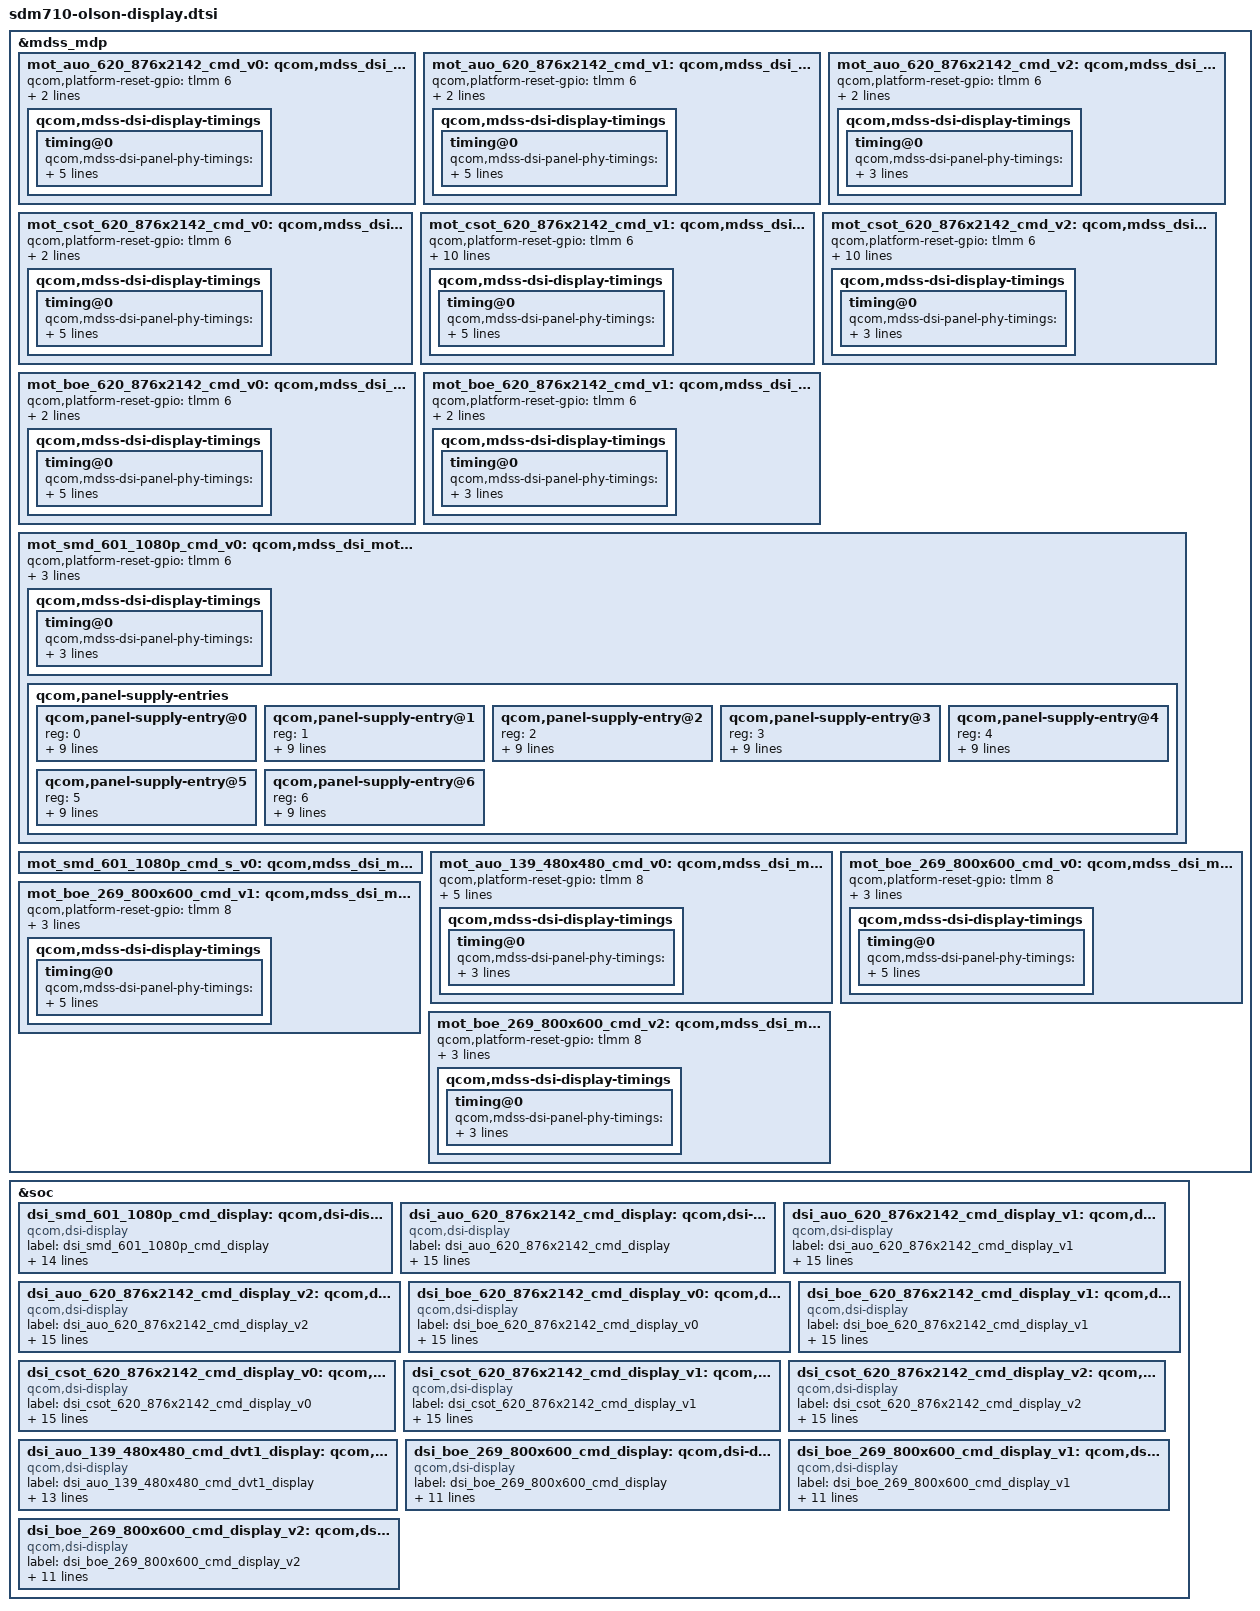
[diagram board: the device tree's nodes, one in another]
/* Copyright (c) 2019, The Linux Foundation. All rights reserved.
 *
 * This program is free software; you can redistribute it and/or modify
 * it under the terms of the GNU General Public License version 2 and
 * only version 2 as published by the Free Software Foundation.
 *
 * This program is distributed in the hope that it will be useful,
 * but WITHOUT ANY WARRANTY; without even the implied warranty of
 * MERCHANTABILITY or FITNESS FOR A PARTICULAR PURPOSE.  See the
 * GNU General Public License for more details.
 */

&mdss_mdp {
	/* Primary Display: AUO */
	mot_auo_620_876x2142_cmd_v0: qcom,mdss_dsi_mot_auo_620_876x2142_cmd_v0 {
		#include "dsi-panel-mot-auo-620-876x2142-olson-cmd-common.dtsi"
	};

	mot_auo_620_876x2142_cmd_v1: qcom,mdss_dsi_mot_auo_620_876x2142_cmd_v1 {
		#include "dsi-panel-mot-auo-620-876x2142-olson-cmd-common.dtsi"
	};

	mot_auo_620_876x2142_cmd_v2: qcom,mdss_dsi_mot_auo_620_876x2142_cmd_v2 {
		#include "dsi-panel-mot-auo-620-876x2142-olson-cmd-common.dtsi"
	};

        /* Primary Display:  CSOT */
        mot_csot_620_876x2142_cmd_v0: qcom,mdss_dsi_mot_csot_620_876x2142_cmd_v0 {
		#include "dsi-panel-mot-csot-620-876x2142-olson-cmd-common.dtsi"
	};

	mot_csot_620_876x2142_cmd_v1: qcom,mdss_dsi_mot_csot_620_876x2142_cmd_v1 {
		#include "dsi-panel-mot-csot-620-876x2142-olson-cmd-common.dtsi"
	};
	mot_csot_620_876x2142_cmd_v2: qcom,mdss_dsi_mot_csot_620_876x2142_cmd_v2 {
		#include "dsi-panel-mot-csot-620-876x2142-olson-cmd-common.dtsi"
	};
	/* Primary Display:  BOE */
	mot_boe_620_876x2142_cmd_v0: qcom,mdss_dsi_mot_boe_620_876x2142_cmd_v0 {
		#include "dsi-panel-mot-boe-620-876x2142-olson-cmd-common.dtsi"
	};

	/* Primary Display:  BOE */
	mot_boe_620_876x2142_cmd_v1: qcom,mdss_dsi_mot_boe_620_876x2142_cmd_v1 {
		#include "dsi-panel-mot-boe-620-876x2142-olson-cmd-common.dtsi"
	};

	/* Primary Display:  SMD */
	mot_smd_601_1080p_cmd_v0: qcom,mdss_dsi_mot_smd_601_1080p_cmd_v0 {
		#include "dsi-panel-mot-smd-601-1080p-olson-cmd-common.dtsi"
	};

	mot_smd_601_1080p_cmd_s_v0: qcom,mdss_dsi_mot_smd_601_1080p_cmd_s_v0 {
		#include "dsi-panel-mot-smd-601-1080p-olson-cmd-common.dtsi"
	};

	/* Secondary Display: AUO */
	mot_auo_139_480x480_cmd_v0: qcom,mdss_dsi_mot_auo_139_480x480_cmd_v0 {
		#include "dsi-panel-mot-auo-139-480x480-olson-cmd-common.dtsi"
	};

	/* Secondary Display: BOE */
	mot_boe_269_800x600_cmd_v0: qcom,mdss_dsi_mot_boe_269_800x600_cmd_v0 {
		#include "dsi-panel-mot-boe-269-800x600-olson-cmd-common.dtsi"
	};

	mot_boe_269_800x600_cmd_v1: qcom,mdss_dsi_mot_boe_269_800x600_cmd_v1 {
		#include "dsi-panel-mot-boe-269-800x600-olson-cmd-common.dtsi"
	};

	mot_boe_269_800x600_cmd_v2: qcom,mdss_dsi_mot_boe_269_800x600_cmd_v2 {
		#include "dsi-panel-mot-boe-269-800x600-olson-cmd-common.dtsi"
	};
};

&soc {
	/* Please keep all the "primary" panel nodes together */
	dsi_smd_601_1080p_cmd_display: qcom,dsi-display@18 {
		compatible = "qcom,dsi-display";
		label = "dsi_smd_601_1080p_cmd_display";
		qcom,display-type = "primary";

		qcom,dsi-ctrl = <&mdss_dsi0>;
		qcom,dsi-phy = <&mdss_dsi_phy0>;
		clocks = <&mdss_dsi0_pll BYTECLK_MUX_0_CLK>,
			<&mdss_dsi0_pll PCLK_MUX_0_CLK>;
		clock-names = "mux_byte_clk", "mux_pixel_clk";

		pinctrl-names = "panel_active", "panel_suspend";
		pinctrl-0 = <&sde_dsi_active &sde_te_active>;
		pinctrl-1 = <&sde_dsi_suspend &sde_te_suspend>;
		qcom,platform-te-gpio = <&tlmm 10 0>;
		qcom,dsi-panel = <&mot_smd_601_1080p_cmd_v0>;
		vci_disp-supply = <&vci_disp_vreg>;
		vio_disp-supply = <&vio_disp_vreg>;
		lab-supply = <&lab_regulator>;
		ibb-supply = <&ibb_regulator>;
		oledb-supply = <&pm660a_oledb>;
	};

	dsi_auo_620_876x2142_cmd_display: qcom,dsi-display@20 {
		compatible = "qcom,dsi-display";
		label = "dsi_auo_620_876x2142_cmd_display";
		qcom,display-type = "primary";

		qcom,dsi-ctrl = <&mdss_dsi0>;
		qcom,dsi-phy = <&mdss_dsi_phy0>;
		clocks = <&mdss_dsi0_pll BYTECLK_MUX_0_CLK>,
				<&mdss_dsi0_pll PCLK_MUX_0_CLK>;
		clock-names = "mux_byte_clk", "mux_pixel_clk";

		pinctrl-names = "panel_active", "panel_suspend";
		pinctrl-0 = <&sde_dsi_active &sde_te_active>;
		pinctrl-1 = <&sde_dsi_suspend &sde_te_suspend>;
		qcom,platform-te-gpio = <&tlmm 10 0>;
		qcom,dsi-panel = <&mot_auo_620_876x2142_cmd_v0>;
		l11_disp-supply = <&pm660_l11>;
		vci_disp-supply = <&vci_disp_vreg>;
		vio_disp-supply = <&vio_disp_vreg>;
		lab-supply = <&lab_regulator>;
		ibb-supply = <&ibb_regulator>;
		oledb-supply = <&pm660a_oledb>;
	};

	dsi_auo_620_876x2142_cmd_display_v1: qcom,dsi-display@24 {
		compatible = "qcom,dsi-display";
		label = "dsi_auo_620_876x2142_cmd_display_v1";
		qcom,display-type = "primary";

		qcom,dsi-ctrl = <&mdss_dsi0>;
		qcom,dsi-phy = <&mdss_dsi_phy0>;
		clocks = <&mdss_dsi0_pll BYTECLK_MUX_0_CLK>,
				<&mdss_dsi0_pll PCLK_MUX_0_CLK>;
		clock-names = "mux_byte_clk", "mux_pixel_clk";

		pinctrl-names = "panel_active", "panel_suspend";
		pinctrl-0 = <&sde_dsi_active &sde_te_active>;
		pinctrl-1 = <&sde_dsi_suspend &sde_te_suspend>;
		qcom,platform-te-gpio = <&tlmm 10 0>;
		qcom,dsi-panel = <&mot_auo_620_876x2142_cmd_v1>;
		l11_disp-supply = <&pm660_l11>;
		vci_disp-supply = <&vci_disp_vreg>;
		vio_disp-supply = <&vio_disp_vreg>;
		lab-supply = <&lab_regulator>;
		ibb-supply = <&ibb_regulator>;
		oledb-supply = <&pm660a_oledb>;
	};

	dsi_auo_620_876x2142_cmd_display_v2: qcom,dsi-display@26 {
		compatible = "qcom,dsi-display";
		label = "dsi_auo_620_876x2142_cmd_display_v2";
		qcom,display-type = "primary";

		qcom,dsi-ctrl = <&mdss_dsi0>;
		qcom,dsi-phy = <&mdss_dsi_phy0>;
		clocks = <&mdss_dsi0_pll BYTECLK_MUX_0_CLK>,
			<&mdss_dsi0_pll PCLK_MUX_0_CLK>;
		clock-names = "mux_byte_clk", "mux_pixel_clk";

		pinctrl-names = "panel_active", "panel_suspend";
		pinctrl-0 = <&sde_dsi_active &sde_te_active>;
		pinctrl-1 = <&sde_dsi_suspend &sde_te_suspend>;
		qcom,platform-te-gpio = <&tlmm 10 0>;
		qcom,dsi-panel = <&mot_auo_620_876x2142_cmd_v2>;
		l11_disp-supply = <&pm660_l11>;
		vci_disp-supply = <&vci_disp_vreg>;
		vio_disp-supply = <&vio_disp_vreg>;
		lab-supply = <&lab_regulator>;
		ibb-supply = <&ibb_regulator>;
		oledb-supply = <&pm660a_oledb>;
	};

	dsi_boe_620_876x2142_cmd_display_v0: qcom,dsi-display@28 {
		compatible = "qcom,dsi-display";
		label = "dsi_boe_620_876x2142_cmd_display_v0";
		qcom,display-type = "primary";

		qcom,dsi-ctrl = <&mdss_dsi0>;
		qcom,dsi-phy = <&mdss_dsi_phy0>;
		clocks = <&mdss_dsi0_pll BYTECLK_MUX_0_CLK>,
			<&mdss_dsi0_pll PCLK_MUX_0_CLK>;
		clock-names = "mux_byte_clk", "mux_pixel_clk";

		pinctrl-names = "panel_active", "panel_suspend";
		pinctrl-0 = <&sde_dsi_active &sde_te_active>;
		pinctrl-1 = <&sde_dsi_suspend &sde_te_suspend>;
		qcom,platform-te-gpio = <&tlmm 10 0>;
		qcom,dsi-panel = <&mot_boe_620_876x2142_cmd_v0>;
		l11_disp-supply = <&pm660_l11>;
		vci_disp-supply = <&vci_disp_vreg>;
		vio_disp-supply = <&vio_disp_vreg>;
		lab-supply = <&lab_regulator>;
		ibb-supply = <&ibb_regulator>;
		oledb-supply = <&pm660a_oledb>;
	};

	dsi_boe_620_876x2142_cmd_display_v1: qcom,dsi-display@29 {
		compatible = "qcom,dsi-display";
		label = "dsi_boe_620_876x2142_cmd_display_v1";
		qcom,display-type = "primary";

		qcom,dsi-ctrl = <&mdss_dsi0>;
		qcom,dsi-phy = <&mdss_dsi_phy0>;
		clocks = <&mdss_dsi0_pll BYTECLK_MUX_0_CLK>,
			<&mdss_dsi0_pll PCLK_MUX_0_CLK>;
		clock-names = "mux_byte_clk", "mux_pixel_clk";

		pinctrl-names = "panel_active", "panel_suspend";
		pinctrl-0 = <&sde_dsi_active &sde_te_active>;
		pinctrl-1 = <&sde_dsi_suspend &sde_te_suspend>;
		qcom,platform-te-gpio = <&tlmm 10 0>;
		qcom,dsi-panel = <&mot_boe_620_876x2142_cmd_v1>;
		l11_disp-supply = <&pm660_l11>;
		vci_disp-supply = <&vci_disp_vreg>;
		vio_disp-supply = <&vio_disp_vreg>;
		lab-supply = <&lab_regulator>;
		ibb-supply = <&ibb_regulator>;
		oledb-supply = <&pm660a_oledb>;
	};
	dsi_csot_620_876x2142_cmd_display_v0: qcom,dsi-display@30 {
		compatible = "qcom,dsi-display";
		label = "dsi_csot_620_876x2142_cmd_display_v0";
		qcom,display-type = "primary";

		qcom,dsi-ctrl = <&mdss_dsi0>;
		qcom,dsi-phy = <&mdss_dsi_phy0>;
		clocks = <&mdss_dsi0_pll BYTECLK_MUX_0_CLK>,
			<&mdss_dsi0_pll PCLK_MUX_0_CLK>;
		clock-names = "mux_byte_clk", "mux_pixel_clk";

		pinctrl-names = "panel_active", "panel_suspend";
		pinctrl-0 = <&sde_dsi_active &sde_te_active>;
		pinctrl-1 = <&sde_dsi_suspend &sde_te_suspend>;
		qcom,platform-te-gpio = <&tlmm 10 0>;
		qcom,dsi-panel = <&mot_csot_620_876x2142_cmd_v0>;
		l11_disp-supply = <&pm660_l11>;
		vci_disp-supply = <&vci_disp_vreg>;
		vio_disp-supply = <&vio_disp_vreg>;
		lab-supply = <&lab_regulator>;
		ibb-supply = <&ibb_regulator>;
		oledb-supply = <&pm660a_oledb>;
	};

	dsi_csot_620_876x2142_cmd_display_v1: qcom,dsi-display@31 {
		compatible = "qcom,dsi-display";
		label = "dsi_csot_620_876x2142_cmd_display_v1";
		qcom,display-type = "primary";

		qcom,dsi-ctrl = <&mdss_dsi0>;
		qcom,dsi-phy = <&mdss_dsi_phy0>;
		clocks = <&mdss_dsi0_pll BYTECLK_MUX_0_CLK>,
			<&mdss_dsi0_pll PCLK_MUX_0_CLK>;
		clock-names = "mux_byte_clk", "mux_pixel_clk";

		pinctrl-names = "panel_active", "panel_suspend";
		pinctrl-0 = <&sde_dsi_active &sde_te_active>;
		pinctrl-1 = <&sde_dsi_suspend &sde_te_suspend>;
		qcom,platform-te-gpio = <&tlmm 10 0>;
		qcom,dsi-panel = <&mot_csot_620_876x2142_cmd_v1>;
		l11_disp-supply = <&pm660_l11>;
		vci_disp-supply = <&vci_disp_vreg>;
		vio_disp-supply = <&vio_disp_vreg>;
		lab-supply = <&lab_regulator>;
		ibb-supply = <&ibb_regulator>;
		oledb-supply = <&pm660a_oledb>;
	};

	dsi_csot_620_876x2142_cmd_display_v2: qcom,dsi-display@32 {
		compatible = "qcom,dsi-display";
		label = "dsi_csot_620_876x2142_cmd_display_v2";
		qcom,display-type = "primary";

		qcom,dsi-ctrl = <&mdss_dsi0>;
		qcom,dsi-phy = <&mdss_dsi_phy0>;
		clocks = <&mdss_dsi0_pll BYTECLK_MUX_0_CLK>,
			<&mdss_dsi0_pll PCLK_MUX_0_CLK>;
		clock-names = "mux_byte_clk", "mux_pixel_clk";

		pinctrl-names = "panel_active", "panel_suspend";
		pinctrl-0 = <&sde_dsi_active &sde_te_active>;
		pinctrl-1 = <&sde_dsi_suspend &sde_te_suspend>;
		qcom,platform-te-gpio = <&tlmm 10 0>;
		qcom,dsi-panel = <&mot_csot_620_876x2142_cmd_v2>;
		l11_disp-supply = <&pm660_l11>;
		vci_disp-supply = <&vci_disp_vreg>;
		vio_disp-supply = <&vio_disp_vreg>;
		lab-supply = <&lab_regulator>;
		ibb-supply = <&ibb_regulator>;
		oledb-supply = <&pm660a_oledb>;
	};
	/* Please keep all the "secondary" panel nodes together */
	dsi_auo_139_480x480_cmd_dvt1_display: qcom,dsi-display@22 {
		compatible = "qcom,dsi-display";
		label = "dsi_auo_139_480x480_cmd_dvt1_display";
		qcom,display-type = "secondary";

		qcom,dsi-ctrl = <&mdss_dsi1>;
		qcom,dsi-phy = <&mdss_dsi_phy1>;
		clocks = <&mdss_dsi1_pll BYTECLK_MUX_1_CLK>,
			<&mdss_dsi1_pll PCLK_MUX_1_CLK>;
		clock-names = "mux_byte_clk", "mux_pixel_clk";

		pinctrl-names = "panel_active", "panel_suspend";
		pinctrl-0 = <&sde_dsi1_active &sde_te1_active
				&ts_sub_rst_active>;
		pinctrl-1 = <&sde_dsi1_suspend &sde_te1_suspend
				&ts_sub_rst_suspend>;
		qcom,platform-te-gpio = <&tlmm 11 0>;
		qcom,dsi-panel = <&mot_auo_139_480x480_cmd_v0>;
		vci_disp-supply = <&vci_disp_sub_vreg>;
		vio_disp-supply = <&vio_disp_sub_vreg>;
	};

	dsi_boe_269_800x600_cmd_display: qcom,dsi-display@23 {
		compatible = "qcom,dsi-display";
		label = "dsi_boe_269_800x600_cmd_display";
		qcom,display-type = "secondary";

		qcom,dsi-ctrl = <&mdss_dsi1>;
		qcom,dsi-phy = <&mdss_dsi_phy1>;
		clocks = <&mdss_dsi1_pll BYTECLK_MUX_1_CLK>,
			<&mdss_dsi1_pll PCLK_MUX_1_CLK>;
		clock-names = "mux_byte_clk", "mux_pixel_clk";

		pinctrl-names = "panel_active", "panel_suspend";
		pinctrl-0 = <&sde_dsi1_active &sde_te1_active>;
		pinctrl-1 = <&sde_dsi1_suspend &sde_te1_suspend>;
		qcom,platform-te-gpio = <&tlmm 11 0>;
		qcom,dsi-panel = <&mot_boe_269_800x600_cmd_v0>;
		vci_disp-supply = <&vci_disp_sub_vreg>;
		vio_disp-supply = <&vio_disp_sub_vreg>;
	};

	dsi_boe_269_800x600_cmd_display_v1: qcom,dsi-display@25 {
		compatible = "qcom,dsi-display";
		label = "dsi_boe_269_800x600_cmd_display_v1";
		qcom,display-type = "secondary";

		qcom,dsi-ctrl = <&mdss_dsi1>;
		qcom,dsi-phy = <&mdss_dsi_phy1>;
		clocks = <&mdss_dsi1_pll BYTECLK_MUX_1_CLK>,
			<&mdss_dsi1_pll PCLK_MUX_1_CLK>;
		clock-names = "mux_byte_clk", "mux_pixel_clk";

		pinctrl-names = "panel_active", "panel_suspend";
		pinctrl-0 = <&sde_dsi1_active &sde_te1_active>;
		pinctrl-1 = <&sde_dsi1_suspend &sde_te1_suspend>;
		qcom,platform-te-gpio = <&tlmm 11 0>;
		qcom,dsi-panel = <&mot_boe_269_800x600_cmd_v1>;
		vci_disp-supply = <&vci_disp_sub_vreg>;
		vio_disp-supply = <&vio_disp_sub_vreg>;
	};

	dsi_boe_269_800x600_cmd_display_v2: qcom,dsi-display@27 {
		compatible = "qcom,dsi-display";
		label = "dsi_boe_269_800x600_cmd_display_v2";
		qcom,display-type = "secondary";

		qcom,dsi-ctrl = <&mdss_dsi1>;
		qcom,dsi-phy = <&mdss_dsi_phy1>;
		clocks = <&mdss_dsi1_pll BYTECLK_MUX_1_CLK>,
			<&mdss_dsi1_pll PCLK_MUX_1_CLK>;
		clock-names = "mux_byte_clk", "mux_pixel_clk";

		pinctrl-names = "panel_active", "panel_suspend";
		pinctrl-0 = <&sde_dsi1_active &sde_te1_active>;
		pinctrl-1 = <&sde_dsi1_suspend &sde_te1_suspend>;
		qcom,platform-te-gpio = <&tlmm 11 0>;
		qcom,dsi-panel = <&mot_boe_269_800x600_cmd_v2>;
		vci_disp-supply = <&vci_disp_sub_vreg>;
		vio_disp-supply = <&vio_disp_sub_vreg>;
	};
};

&mot_smd_601_1080p_cmd_v0 {
        qcom,platform-reset-gpio = <&tlmm 6 0>;
        qcom,mdss-dsi-t-clk-post = <0x0d>;
        qcom,mdss-dsi-t-clk-pre = <0x30>;
        qcom,mdss-mdp-transfer-time-us = <14000>;

        qcom,mdss-dsi-display-timings {
                timing@0{
                        qcom,mdss-dsi-panel-phy-timings = [00 1f 08 08 24 22 08
                                                        08 05 03 04 00];
                        qcom,display-topology = <1 0 1>;
                        qcom,default-topology-index = <0>;
                };
        };

	qcom,panel-supply-entries {
		#address-cells = <1>;
		#size-cells = <0>;

		qcom,panel-supply-entry@0 {
			reg = <0>;
			qcom,supply-name = "l11_disp";
			qcom,supply-min-voltage = <1800000>;
			qcom,supply-max-voltage = <1800000>;
			qcom,supply-enable-load = <300000>;
			qcom,supply-disable-load = <100>;
			qcom,supply-pre-on-sleep = <0>;
			qcom,supply-post-on-sleep = <1>;
			qcom,supply-pre-off-sleep = <3>;
			qcom,supply-post-off-sleep = <0>;
		};

		qcom,panel-supply-entry@1 {
			reg = <1>;
			qcom,supply-name = "vio_disp";
			qcom,supply-min-voltage = <1800000>;
			qcom,supply-max-voltage = <1800000>;
			qcom,supply-enable-load = <300000>;
			qcom,supply-disable-load = <100>;
			qcom,supply-pre-on-sleep = <0>;
			qcom,supply-post-on-sleep = <2>;
			qcom,supply-pre-off-sleep = <0>;
			qcom,supply-post-off-sleep = <0>;
		};

		qcom,panel-supply-entry@2 {
			reg = <2>;
			qcom,supply-name = "vci_disp";
			qcom,supply-min-voltage = <3200000>;
			qcom,supply-max-voltage = <3200000>;
			qcom,supply-enable-load = <300000>;
			qcom,supply-disable-load = <100>;
			qcom,supply-pre-on-sleep = <0>;
			qcom,supply-post-on-sleep = <2>;
			qcom,supply-pre-off-sleep = <11>;
			qcom,supply-post-off-sleep = <0>;
		};

		qcom,panel-supply-entry@3 {
			reg = <3>;
			qcom,supply-name = "lab";
			qcom,supply-min-voltage = <4600000>;
			qcom,supply-max-voltage = <6100000>;
			qcom,supply-enable-load = <100000>;
			qcom,supply-disable-load = <100>;
			qcom,supply-pre-on-sleep = <0>;
			qcom,supply-post-on-sleep = <0>;
			qcom,supply-pre-off-sleep = <0>;
			qcom,supply-post-off-sleep = <0>;
		};

		qcom,panel-supply-entry@4 {
			reg = <4>;
			qcom,supply-name = "ibb";
			qcom,supply-min-voltage = <4000000>;
			qcom,supply-max-voltage = <6300000>;
			qcom,supply-enable-load = <100000>;
			qcom,supply-disable-load = <100>;
			qcom,supply-pre-on-sleep = <0>;
			qcom,supply-post-on-sleep = <0>;
			qcom,supply-pre-off-sleep = <0>;
			qcom,supply-post-off-sleep = <0>;
		};

		qcom,panel-supply-entry@5 {
			reg = <5>;
			qcom,supply-name = "oledb";
			qcom,supply-min-voltage = <5000000>;
			qcom,supply-max-voltage = <8100000>;
			qcom,supply-enable-load = <100000>;
			qcom,supply-disable-load = <100>;
			qcom,supply-pre-on-sleep = <0>;
			qcom,supply-post-on-sleep = <0>;
			qcom,supply-pre-off-sleep = <0>;
			qcom,supply-post-off-sleep = <0>;
		};

		qcom,panel-supply-entry@6 {
			reg = <6>;
			qcom,supply-name = "vio_s_disp";
			qcom,supply-min-voltage = <1800000>;
			qcom,supply-max-voltage = <1800000>;
			qcom,supply-enable-load = <300000>;
			qcom,supply-disable-load = <100>;
			qcom,supply-pre-on-sleep = <0>;
			qcom,supply-post-on-sleep = <1>;
			qcom,supply-pre-off-sleep = <3>;
			qcom,supply-post-off-sleep = <0>;
		};
	};
};

&mot_auo_620_876x2142_cmd_v0 {
	qcom,platform-reset-gpio = <&tlmm 6 0>;
	qcom,mdss-dsi-t-clk-post = <0x0D>;
	qcom,mdss-dsi-t-clk-pre = <0x30>;

	qcom,mdss-dsi-display-timings {
		timing@0{
			qcom,mdss-dsi-panel-phy-timings = [00 1f 08 08 24 22 08
								08 05 03 04 00];
			qcom,display-topology = <1 0 1>;
			qcom,default-topology-index = <0>;
			qcom,mdss-dsi-on-command = [
				15 00 00 00 00 00 02 FE 40
				15 00 00 00 00 00 02 05 06
				15 00 00 00 00 00 02 06 0C
				15 00 00 00 00 00 02 08 06
				15 00 00 00 00 00 02 09 0C
				15 00 00 00 00 00 02 FE 60
				15 00 00 00 00 00 02 38 C4
				15 00 00 00 00 00 02 43 C4
				15 00 00 00 00 00 02 FE 70
				15 00 00 00 00 00 02 7D 35
				15 00 00 00 00 00 02 FE 00
				05 01 00 00 78 00 01 11
				15 00 00 00 00 00 02 35 00
				15 00 00 00 00 00 02 53 20 /* HBM off ,dimming=1frame*/
				15 00 00 00 00 00 02 51 00
				15 00 00 00 00 00 02 55 00      /* ACL OFF */
				05 01 00 00 00 00 01 29];       /* display on */
		};
	};
};

&mot_auo_620_876x2142_cmd_v1 {
	qcom,platform-reset-gpio = <&tlmm 6 0>;
	qcom,mdss-dsi-t-clk-post = <0x0D>;
	qcom,mdss-dsi-t-clk-pre = <0x30>;

	qcom,mdss-dsi-display-timings {
		timing@0{
			qcom,mdss-dsi-panel-phy-timings = [00 1f 08 08 24 22 08
								08 05 03 04 00];
			qcom,display-topology = <1 0 1>;
			qcom,default-topology-index = <0>;
			qcom,mdss-dsi-on-command = [
				15 00 00 00 00 00 02 FE 70 /* Switch to page 70 */
				15 00 00 00 00 00 02 CB 05
				15 00 00 00 00 00 02 7D 31 /* Use source mode */
				15 00 00 00 00 00 02 7E 4A /* Enable source mode linear light curve */
				15 00 00 00 00 00 02 49 00
				15 00 00 00 00 00 02 4A 2E
				15 00 00 00 00 00 02 4B 50
				15 00 00 00 00 00 02 4C 70
				15 00 00 00 00 00 02 4D 9C
				15 00 00 00 00 00 02 4E D0
				15 00 00 00 00 00 02 4F 21
				15 00 00 00 00 00 02 50 90
				15 00 00 00 00 00 02 51 24
				15 00 00 00 00 00 02 AD EA
				15 00 00 00 00 00 02 AE 80
				15 00 00 00 00 00 02 AF 00
				15 00 00 00 00 00 02 B0 50
				15 00 00 00 00 00 02 B1 3A
				15 00 00 00 00 00 02 FE 00 /* switch back to page 0 */
				05 01 00 00 78 00 01 11
				15 00 00 00 00 00 02 35 00
				15 00 00 00 00 00 02 53 20 /* HBM off ,dimming=1frame*/
				15 00 00 00 00 00 02 51 00
				15 00 00 00 00 00 02 55 00      /* ACL OFF */
				05 01 00 00 00 00 01 29];       /* display on */
			};
	};
};

&mot_auo_620_876x2142_cmd_v2 {
	qcom,platform-reset-gpio = <&tlmm 6 0>;
	qcom,mdss-dsi-t-clk-post = <0x0D>;
	qcom,mdss-dsi-t-clk-pre = <0x30>;

	qcom,mdss-dsi-display-timings {
		timing@0{
			qcom,mdss-dsi-panel-phy-timings = [00 1f 08 08 24 22 08
								08 05 03 04 00];
			qcom,display-topology = <1 0 1>;
			qcom,default-topology-index = <0>;
		};
	};
};

&mot_boe_620_876x2142_cmd_v0 {
	qcom,platform-reset-gpio = <&tlmm 6 0>;
	qcom,mdss-dsi-t-clk-post = <0x0D>;
	qcom,mdss-dsi-t-clk-pre = <0x30>;

	qcom,mdss-dsi-display-timings {
		timing@0{
			qcom,mdss-dsi-panel-phy-timings = [00 1f 08 08 24 22 08
								08 05 03 04 00];
			qcom,display-topology = <1 0 1>;
			qcom,default-topology-index = <0>;
			qcom,mdss-dsi-on-command = [
					15 00 00 00 00 00 02 FE D0
					15 00 00 00 00 00 02 99 00
					15 00 00 00 00 00 02 FE 40
					15 00 00 00 00 00 02 74 2E
					15 00 00 00 00 00 02 80 19
					15 00 00 00 00 00 02 FE E0
					15 00 00 00 00 00 02 9A D7
					15 00 00 00 00 00 02 91 19
					15 00 00 00 00 00 02 92 14
					15 00 00 00 00 00 02 FE 40
					15 00 00 00 00 00 02 9A 00
					15 00 00 00 00 00 02 FE 00
					15 00 00 00 00 00 02 35 00
					15 00 00 00 00 00 02 5E 01
					15 00 00 00 00 00 02 C2 08
					15 00 00 00 00 00 02 53 20 /*HBM off ,dimming=1frame*/
					15 00 00 00 00 00 02 55 00	/*ACL OFF */
					15 00 00 00 00 00 02 51 00
					05 01 00 00 78 00 01 11
					05 01 00 00 00 00 01 29];	/* display on */
		};
	};
};

&mot_boe_620_876x2142_cmd_v1 {
	qcom,platform-reset-gpio = <&tlmm 6 0>;
	qcom,mdss-dsi-t-clk-post = <0x0D>;
	qcom,mdss-dsi-t-clk-pre = <0x30>;

	qcom,mdss-dsi-display-timings {
		timing@0{
			qcom,mdss-dsi-panel-phy-timings = [00 1f 08 08 24 22 08
								08 05 03 04 00];
			qcom,display-topology = <1 0 1>;
			qcom,default-topology-index = <0>;
		};
	};
};

&mot_csot_620_876x2142_cmd_v0 {
	qcom,platform-reset-gpio = <&tlmm 6 0>;
	qcom,mdss-dsi-t-clk-post = <0x0D>;
	qcom,mdss-dsi-t-clk-pre = <0x30>;

	qcom,mdss-dsi-display-timings {
		timing@0{
			qcom,mdss-dsi-panel-phy-timings = [00 1f 08 08 24 22 08
								08 05 03 04 00];
			qcom,display-topology = <1 0 1>;
			qcom,default-topology-index = <0>;

			qcom,mdss-dsi-on-command = [
				15 00 00 00 00 00 02 FE 40 /*switch CMD2*/
				15 00 00 00 00 00 02 9A 00 /*corner R function off, 0x00 for off, 0x01 for on*/
				15 00 00 00 00 00 02 FE 00 /*return to CMD0*/
				05 01 00 00 78 00 01 11
				15 00 00 00 00 00 02 35 00
				15 00 00 00 00 00 02 53 20 /* HBM off ,dimming=1frame*/
				15 00 00 00 00 00 02 51 00
				15 00 00 00 00 00 02 55 00      /* ACL OFF */
				05 01 00 00 00 00 01 29];	/* display on */
		};
	};
};

&mot_csot_620_876x2142_cmd_v1 {
	qcom,platform-reset-gpio = <&tlmm 6 0>;
	qcom,mdss-dsi-t-clk-post = <0x0D>;
	qcom,mdss-dsi-t-clk-pre = <0x30>;

	qcom,bklt-dcs-2bytes-enabled;
	qcom,mdss-dsi-bl-min-level = <3>;
	qcom,mdss-dsi-bl-max-level = <2047>;

	qcom,mdss-dsi-hbm-on-command = [39 01 00 00 00 00 03 51 0F FF];
	qcom,mdss-dsi-hbm-off-command = [39 01 00 00 00 00 03 51 07 FF];

	qcom,mdss-dsi-panel-hbm-is-51cmd;

	qcom,mdss-dsi-display-timings {
		timing@0{
			qcom,mdss-dsi-panel-phy-timings = [00 1f 08 08 24 22 08
								08 05 03 04 00];
			qcom,display-topology = <1 0 1>;
			qcom,default-topology-index = <0>;

			qcom,mdss-dsi-on-command = [
				15 00 00 00 00 00 02 FE 40 /*switch CMD2*/
				15 00 00 00 00 00 02 9A 00 /* corner R function off, 0x00 for off, 0x01 for on*/
				15 00 00 00 00 00 02 6F 02 /*swire update by vsync*/
				15 00 00 00 00 00 02 FE 00
				15 00 00 00 00 00 02 5E 01 /* swire control Enable */
				15 00 00 00 00 00 02 FE E0 /* */
				15 00 00 00 00 00 02 C3 00 /* Enable Avg Y */
				15 00 00 00 00 00 02 8B 12 /* ops dimming off*/
				15 00 00 00 00 00 02 8E 21 /* Step width*/
				15 00 00 00 00 00 02 90 14 /* First pulse width*/
				15 00 00 00 00 00 02 FE 70 /* */
				15 00 00 00 00 00 02 11 C0 /* Ops_ref_bc */
				15 00 00 00 00 00 02 17 00 /* opsen_3mode */
				/* Lookup table setting swire pulse */
				15 00 00 00 00 00 02 FE E0 /* */
				15 00 00 00 00 00 02 91 19 /* lut1 = -3v */
				15 00 00 00 00 00 02 92 19 /* lut2 = -3v */
				15 00 00 00 00 00 02 93 19 /* lut3 = -3v */
				15 00 00 00 00 00 02 94 19 /* lut4 = -3v */
				15 00 00 00 00 00 02 95 0F /* lut5 = -3v */
				15 00 00 00 00 00 02 96 0F /* lut6 = -3v */
				15 00 00 00 00 00 02 97 0F /* lut7 = -3v */
				15 00 00 00 00 00 02 98 0F /* lut8 = -3v */
				15 00 00 00 00 00 02 99 0F /* lut9 = -3v */
				/* Lookup table setting 51 ratio */
				15 00 00 00 00 00 02 9A 7F /* lut1 = 000~7FF */
				15 00 00 00 00 00 02 9B 7F /* lut2 = 000~7FF */
				15 00 00 00 00 00 02 9C 7F /* lut3 = 000~7FF */
				15 00 00 00 00 00 02 9D 7F /* lut4 = 800~7FF */
				15 00 00 00 00 00 02 9E FF /* lut5 = 800~7FF */
				15 00 00 00 00 00 02 9F FF /* lut6 = 800~7FF */
				15 00 00 00 00 00 02 A0 FF /* lut7 = 800~7FF */
				15 00 00 00 00 00 02 A2 FF /* lut8 = 800~7FF */
				15 00 00 00 00 00 02 FE 00
				15 00 00 00 00 00 02 C2 08
				05 01 00 00 78 00 01 11
				15 00 00 00 00 00 02 35 00
				15 00 00 00 00 00 02 53 20 /* HBM off ,dimming=1frame*/
				39 00 00 00 00 00 03 51 00 00
				15 00 00 00 00 00 02 55 00      /* ACL OFF */
				05 01 00 00 00 00 01 29];       /* display on */
		};
	};
};

&mot_csot_620_876x2142_cmd_v2 {
	qcom,platform-reset-gpio = <&tlmm 6 0>;
	qcom,mdss-dsi-t-clk-post = <0x0D>;
	qcom,mdss-dsi-t-clk-pre = <0x30>;

	qcom,bklt-dcs-2bytes-enabled;
	qcom,mdss-dsi-bl-min-level = <3>;
	qcom,mdss-dsi-bl-max-level = <2047>;

	qcom,mdss-dsi-hbm-on-command = [39 01 00 00 00 00 03 51 0F FF];
	qcom,mdss-dsi-hbm-off-command = [39 01 00 00 00 00 03 51 07 FF];

	qcom,mdss-dsi-panel-hbm-is-51cmd;

	qcom,mdss-dsi-display-timings {
		timing@0{
			qcom,mdss-dsi-panel-phy-timings = [00 1f 08 08 24 22 08
								08 05 03 04 00];
			qcom,display-topology = <1 0 1>;
			qcom,default-topology-index = <0>;
		};
	};
};

/*
 * The CLI display of the DVT1 is a in-cell display which has one controller
 * to control both the display and touch, therefore the touch reset will
 * be part of the display init and deinit seq. This in-cell display is only
 * used in the DVT1, therefore for temporarty solution is using current display
 * feature which is using qcom,panel-mode-gpio as the touch reset GPIO
 */
&mot_auo_139_480x480_cmd_v0 {
	qcom,platform-reset-gpio = <&tlmm 8 0>;
	qcom,mdss-dsi-mode-sel-gpio-state = "single_port";
	qcom,panel-mode-gpio = <&tlmm 99 0>;
	qcom,mdss-dsi-t-clk-post = <0x0a>;
	qcom,mdss-dsi-t-clk-pre = <0x1C>;
	qcom,mdss-mdp-transfer-time-us = <14000>;

	qcom,mdss-dsi-display-timings {
		timing@0{
			qcom,mdss-dsi-panel-phy-timings = [00 11 03 04 1E 1E 04
								04 02 03 04 00];
			qcom,display-topology = <1 0 1>;
			qcom,default-topology-index = <0>;
		};
	};
};

&mot_boe_269_800x600_cmd_v0 {
	qcom,platform-reset-gpio = <&tlmm 8 0>;
	qcom,mdss-dsi-t-clk-post = <0x0a>;
	qcom,mdss-dsi-t-clk-pre = <0x1B>;
	qcom,mdss-mdp-transfer-time-us = <14000>;

	qcom,mdss-dsi-display-timings {
		timing@0{
			qcom,mdss-dsi-panel-phy-timings = [00 10 03 03 1E 1E 04
								04 02 03 04 00];
			qcom,display-topology = <1 0 1>;
			qcom,default-topology-index = <0>;
			qcom,mdss-dsi-on-command = [
				15 00 00 00 00 00 02 FE 72
				15 00 00 00 00 00 02 10 85
				15 00 00 00 00 00 02 FE 40 /* Switch to CMD2 */
				15 00 00 00 00 00 02 2F 80 /* fixed charged pump of power */
				15 00 00 00 00 00 02 31 80
				15 00 00 00 00 00 02 33 80
				15 00 00 00 00 00 02 35 80
				15 00 00 00 00 00 02 FE 00 /* Switch back CMD0 */
				05 01 00 00 78 00 01 11
				15 00 00 00 00 00 02 35 00
				15 00 00 00 00 00 02 53 20 /* HBM off ,dimming=1frame*/
				15 00 00 00 00 00 02 51 00
				15 00 00 00 00 00 02 55 00 /* ACL OFF */
				05 01 00 00 00 00 01 29];       /* display on */
		};
	};
};

&mot_boe_269_800x600_cmd_v1 {
	qcom,platform-reset-gpio = <&tlmm 8 0>;
	qcom,mdss-dsi-t-clk-post = <0x0a>;
	qcom,mdss-dsi-t-clk-pre = <0x1B>;
	qcom,mdss-mdp-transfer-time-us = <14000>;

	qcom,mdss-dsi-display-timings {
		timing@0{
			qcom,mdss-dsi-panel-phy-timings = [00 10 03 03 1E 1E 04
								04 02 03 04 00];
			qcom,display-topology = <1 0 1>;
			qcom,default-topology-index = <0>;
			qcom,mdss-dsi-on-command = [
				15 00 00 00 00 00 02 FE 40 /* Switch to CMD2 */
				15 00 00 00 00 00 02 2F 80 /* Fixed charged pump of power */
				15 00 00 00 00 00 02 31 80
				15 00 00 00 00 00 02 33 80
				15 00 00 00 00 00 02 35 80
				15 00 00 00 00 00 02 24 50
				15 00 00 00 00 00 02 47 13
				15 00 00 00 00 00 02 FE 50
				15 00 00 00 00 00 02 C0 20
				15 00 00 00 00 00 02 FE 60 /* Switch to CMD2 */
				15 00 00 00 00 00 02 95 CE /* EM pull high */
				15 00 00 00 00 00 02 FE 00 /* Switch back CMD0 */
				05 01 00 00 78 00 01 11
				15 00 00 00 00 00 02 35 00
				15 00 00 00 00 00 02 53 20 /* HBM off ,dimming=1frame*/
				15 00 00 00 00 00 02 51 00
				15 00 00 00 00 00 02 55 00 /* ACL OFF */
				05 01 00 00 00 00 01 29];       /* display on */
		};
	};
};

&mot_boe_269_800x600_cmd_v2 {
	qcom,platform-reset-gpio = <&tlmm 8 0>;
	qcom,mdss-dsi-t-clk-post = <0x0a>;
	qcom,mdss-dsi-t-clk-pre = <0x1B>;
	qcom,mdss-mdp-transfer-time-us = <14000>;

	qcom,mdss-dsi-display-timings {
		timing@0{
			qcom,mdss-dsi-panel-phy-timings = [00 10 03 03 1E 1E 04
								04 02 03 04 00];
			qcom,display-topology = <1 0 1>;
			qcom,default-topology-index = <0>;
		};
	};
};
